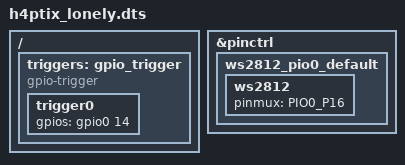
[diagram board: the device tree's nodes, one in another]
/dts-v1/;

#include "h4ptix_common.dtsi"

/ {
  triggers: gpio_trigger {
    compatible = "gpio-trigger";

    trigger0 {
      gpios = <&gpio0 14 GPIO_ACTIVE_HIGH>;
    };
  };
};

&pinctrl {
  ws2812_pio0_default: ws2812_pio0_default {
    ws2812 {
      pinmux = <PIO0_P16>;
    };
  };
};
